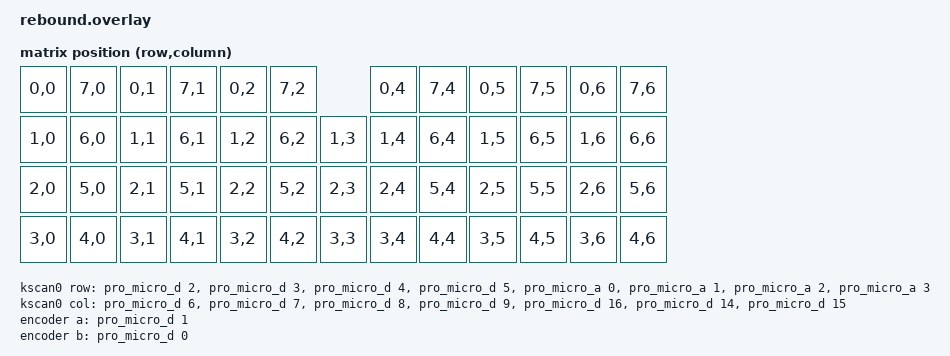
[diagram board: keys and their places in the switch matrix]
// This file was generated from a template. Edit it to match your keyboard.
// See https://zmk.dev/docs/development/hardware-integration/new-shield for more
// instructions.

#include "rebound-layouts.dtsi"
#include <dt-bindings/zmk/matrix_transform.h>
#include <physical_layouts.dtsi>

/ {
    chosen {
        zmk,kscan = &kscan0;
        zmk,matrix_transform = &default_transform;
        zmk,physical-layout = &physical_layout0;
        zmk,underglow = &led_strip;
    };

    default_transform: keymap_transform_0 {
        compatible = "zmk,matrix-transform";
        columns = <7>;
        rows = <8>;
        map = <
RC(0,0) RC(7,0) RC(0,1) RC(7,1) RC(0,2) RC(7,2)         RC(0,4) RC(7,4) RC(0,5) RC(7,5) RC(0,6) RC(7,6)
RC(1,0) RC(6,0) RC(1,1) RC(6,1) RC(1,2) RC(6,2) RC(1,3) RC(1,4) RC(6,4) RC(1,5) RC(6,5) RC(1,6) RC(6,6)
RC(2,0) RC(5,0) RC(2,1) RC(5,1) RC(2,2) RC(5,2) RC(2,3) RC(2,4) RC(5,4) RC(2,5) RC(5,5) RC(2,6) RC(5,6)
RC(3,0) RC(4,0) RC(3,1) RC(4,1) RC(3,2) RC(4,2) RC(3,3) RC(3,4) RC(4,4) RC(3,5) RC(4,5) RC(3,6) RC(4,6)
        >;
    };
    physical_layout0: physical_layout_0 { // First physical layout, use different naming for other layouts
        compatible = "zmk,physical-layout";
        display-name = "Default Layout";
        kscan = <&kscan0>; // Label of the kscan node, optional if all layouts use the same
        transform = <&default_transform>; // Label of the matrix transform for this layout
    };


    kscan0: kscan_0 {
        compatible = "zmk,kscan-gpio-matrix";
        diode-direction = "row2col";

        col-gpios
            = <&pro_micro_d 6 (GPIO_ACTIVE_HIGH | GPIO_PULL_DOWN)>
            , <&pro_micro_d 7 (GPIO_ACTIVE_HIGH | GPIO_PULL_DOWN)>
            , <&pro_micro_d 8 (GPIO_ACTIVE_HIGH | GPIO_PULL_DOWN)>
            , <&pro_micro_d 9 (GPIO_ACTIVE_HIGH | GPIO_PULL_DOWN)>
            , <&pro_micro_d 16 (GPIO_ACTIVE_HIGH | GPIO_PULL_DOWN)>
            , <&pro_micro_d 14 (GPIO_ACTIVE_HIGH | GPIO_PULL_DOWN)>
	      , <&pro_micro_d 15 (GPIO_ACTIVE_HIGH | GPIO_PULL_DOWN)>
            ;

        row-gpios
            = <&pro_micro_d 2 GPIO_ACTIVE_HIGH>
            , <&pro_micro_d 3 GPIO_ACTIVE_HIGH>
            , <&pro_micro_d 4 GPIO_ACTIVE_HIGH>
            , <&pro_micro_d 5 GPIO_ACTIVE_HIGH>
            , <&pro_micro_a 0 GPIO_ACTIVE_HIGH>
            , <&pro_micro_a 1 GPIO_ACTIVE_HIGH>
            , <&pro_micro_a 2 GPIO_ACTIVE_HIGH>
            , <&pro_micro_a 3 GPIO_ACTIVE_HIGH>
            ;
    };

    encoder: encoder {
        compatible = "alps,ec11";
        a-gpios = <&pro_micro_d 1 (GPIO_ACTIVE_HIGH | GPIO_PULL_UP)>;
        b-gpios = <&pro_micro_d 0 (GPIO_ACTIVE_HIGH | GPIO_PULL_UP)>;
        resolution = <2>;
        status = "okay";
    };

    sensors {
        compatible = "zmk,keymap-sensors";
        sensors = <&encoder>;
    };

    spi1 {
  compatible = "nordic,nrf-spim";
  status = "okay";
  mosi-pin = <9>;
  // Unused pins, needed for SPI definition, but not used by the ws2812 driver itself.
  sck-pin = <5>;
  miso-pin = <7>;

  led_strip: ws2812@0 {
    compatible = "worldsemi,ws2812-spi";
    label = "WS2812";

    /* SPI */
    reg = <0>; /* ignored, but necessary for SPI bindings */
    spi-max-frequency = <4000000>;

    /* WS2812 */
    chain-length = <20>; /* number of LEDs */
    spi-one-frame = <0x70>;
    spi-zero-frame = <0x40>;
  };
};


};
